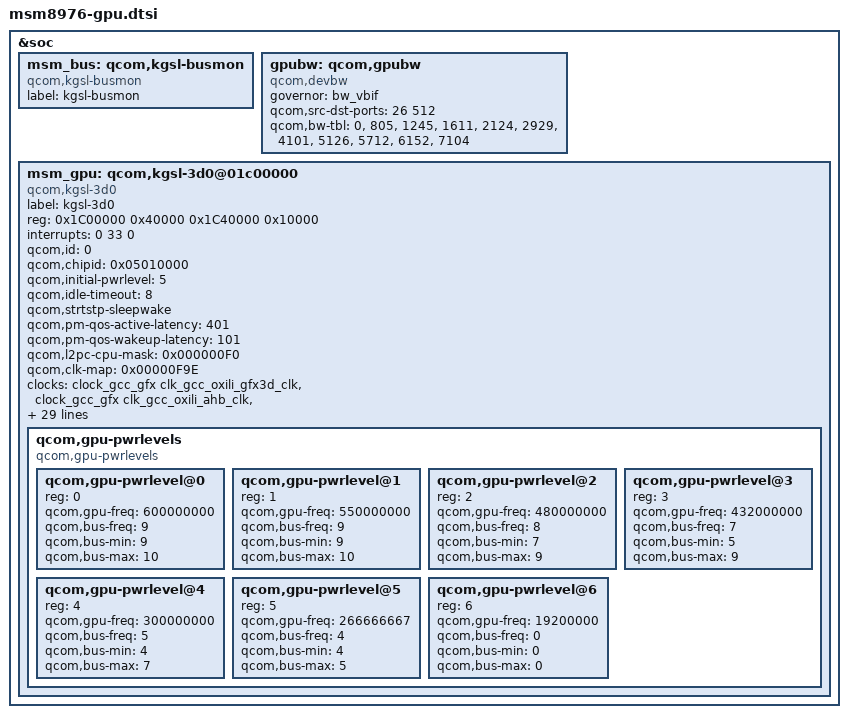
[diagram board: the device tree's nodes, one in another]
/* Copyright (c) 2015-2016, The Linux Foundation. All rights reserved.
 *
 * This program is free software; you can redistribute it and/or modify
 * it under the terms of the GNU General Public License version 2 and
 * only version 2 as published by the Free Software Foundation.
 *
 * This program is distributed in the hope that it will be useful,
 * but WITHOUT ANY WARRANTY; without even the implied warranty of
 * MERCHANTABILITY or FITNESS FOR A PARTICULAR PURPOSE.  See the
 * GNU General Public License for more details.
 */

&soc {
	msm_bus: qcom,kgsl-busmon{
		label = "kgsl-busmon";
		compatible = "qcom,kgsl-busmon";
	};

	/* Bus governor */
	gpubw: qcom,gpubw {
		compatible = "qcom,devbw";
		governor = "bw_vbif";
		qcom,src-dst-ports = <26 512>;
		qcom,bw-tbl =
			< 0 >,    /* off                            */
			< 805  >, /* DDR: 105.6 MHz BIMC:  52.8 MHz */
			< 1245 >, /* DDR: 163.2 MHz BIMC:  81.6 MHz */
			< 1611 >, /* DDR: 211.2 MHz BIMC: 105.6 MHz */
			< 2124 >, /* DDR: 278.4 MHz BIMC: 139.2 MHz */
			< 2929 >, /* DDR: 384.0 MHz BIMC: 192.0 MHz */
			< 4101 >, /* DDR: 537.6 MHz BIMC: 268.8 MHz */
			< 5126 >, /* DDR: 672.0 MHz BIMC: 336.0 MHz */
			< 5712 >, /* DDR: 748.8 MHz BIMC: 374.4 MHz */
			< 6152 >, /* DDR: 806.4 MHz BIMC: 403.2 MHz */
			< 7104 >; /* DDR: 931.2 MHz BIMC: 465.6 MHz */
	};

	msm_gpu: qcom,kgsl-3d0@01c00000 {
		label = "kgsl-3d0";
		compatible = "qcom,kgsl-3d0", "qcom,kgsl-3d";
		reg = <0x1C00000 0x40000
			   0x1C40000 0x10000>;
		reg-names = "kgsl_3d0_reg_memory" , "kgsl_3d0_shader_memory";
		interrupts = <0 33 0>;
		interrupt-names = "kgsl_3d0_irq";
		qcom,id = <0>;

		qcom,chipid = <0x05010000>;

		qcom,initial-pwrlevel = <5>;

		qcom,idle-timeout = <8>; //<HZ/12>
		qcom,strtstp-sleepwake;

		qcom,pm-qos-active-latency = <401>;
		qcom,pm-qos-wakeup-latency = <101>;

		/* Avoid L2PC on big cluster CPUs (CPU 4,5,6,7) */
		qcom,l2pc-cpu-mask = <0x000000F0>;

		/*
		 * Clocks = KGSL_CLK_CORE | KGSL_CLK_IFACE | KGSL_CLK_MEM |
		 * KGSL_CLK_MEM_IFACE | KGSL_CLK_RBBMTIMER |
		 * KGSL_CLK_GFX_GTCU  | KGSL_CLK_GFX_GTBU |
		 * KGSL_CLK_GFX_GTBU1 | KGSL_CLK_AON
		 */
		qcom,clk-map = <0x00000F9E>;

	clocks = <&clock_gcc_gfx clk_gcc_oxili_gfx3d_clk>,
		 <&clock_gcc_gfx clk_gcc_oxili_ahb_clk>,
		 <&clock_gcc_gfx clk_gcc_oxili_gmem_clk>,
		 <&clock_gcc_gfx clk_gcc_bimc_gfx_clk>,
		 <&clock_gcc_gfx clk_gcc_gtcu_ahb_clk>,
		 <&clock_gcc_gfx clk_gcc_gfx_tcu_clk>,
		 <&clock_gcc_gfx clk_gcc_gfx_tbu_clk>,
		 <&clock_gcc_gfx clk_gcc_gfx_1_tbu_clk>,
		 <&clock_gcc_gfx clk_gcc_oxili_timer_clk>,
		 <&clock_gcc_gfx clk_gcc_oxili_aon_clk>;

	clock-names =   "core_clk", "iface_clk", "mem_clk",
			"mem_iface_clk", "gtcu_iface_clk",
			"gtcu_clk", "gtbu_clk", "gtbu1_clk",
			"rbbmtimer_clk", "aon_clk";


		/* Bus Scale Settings */
		qcom,gpubw-dev = <&gpubw>;
		qcom,bus-control;
		qcom,bus-width = <16>;
		qcom,msm-bus,name = "grp3d";
		qcom,msm-bus,num-cases = <11>;
		qcom,msm-bus,num-paths = <1>;
		qcom,msm-bus,vectors-KBps =
				<26 512 0 0>,	    /*  off          */
				<26 512 0 844800>,  /* 1. 105.6  MHz */
				<26 512 0 1305600>, /* 2. 163.2  MHz */
				<26 512 0 1689600>, /* 3. 211.2  MHz */
				<26 512 0 2227200>, /* 4. 278.4  MHz */
				<26 512 0 3072000>, /* 5. 384.0  MHz */
				<26 512 0 4300800>, /* 6. 537.6  MHz */
				<26 512 0 5376000>, /* 7. 672.0  MHz */
				<26 512 0 5990400>, /* 8. 748.8  MHz */
				<26 512 0 6451200>, /* 9. 806.4  MHz */
				<26 512 0 7449600>; /*10. 931.2  MHz */

		/* GDSC oxili regulators */
		vddcx-supply = <&gdsc_oxili_cx>;
		vdd-supply = <&gdsc_oxili_gx>;

		/* IOMMU Data */
                iommu = <&gfx_iommu>;

		/* Trace bus */
		coresight-id = <67>;
		coresight-name = "coresight-gfx";
		coresight-nr-inports = <0>;
		coresight-outports = <0>;
		coresight-child-list = <&funnel_in0>;
		coresight-child-ports = <4>;

		/* Power levels */
		qcom,gpu-pwrlevels {
			#address-cells = <1>;
			#size-cells = <0>;

			compatible = "qcom,gpu-pwrlevels";

			/* TURBO */
			qcom,gpu-pwrlevel@0 {
				reg = <0>;
				qcom,gpu-freq = <600000000>;
				qcom,bus-freq = <9>;
				qcom,bus-min = <9>;
				qcom,bus-max = <10>;
			};

			/* TURBO */
			qcom,gpu-pwrlevel@1 {
				reg = <1>;
				qcom,gpu-freq = <550000000>;
				qcom,bus-freq = <9>;
				qcom,bus-min = <9>;
				qcom,bus-max = <10>;
			};

			/* NOM+ */
			qcom,gpu-pwrlevel@2 {
				reg = <2>;
				qcom,gpu-freq = <480000000>;
				qcom,bus-freq = <8>;
				qcom,bus-min = <7>;
				qcom,bus-max = <9>;
			};

			/* NOM */
			qcom,gpu-pwrlevel@3 {
				reg = <3>;
				qcom,gpu-freq = <432000000>;
				qcom,bus-freq = <7>;
				qcom,bus-min = <5>;
				qcom,bus-max = <9>;
			};

			/* SVS */
			qcom,gpu-pwrlevel@4 {
				reg = <4>;
				qcom,gpu-freq = <300000000>;
				qcom,bus-freq = <5>;
				qcom,bus-min = <4>;
				qcom,bus-max = <7>;
			};

			/* Low SVS+ */
			qcom,gpu-pwrlevel@5 {
				reg = <5>;
				qcom,gpu-freq = <266666667>;
				qcom,bus-freq = <4>;
				qcom,bus-min = <4>;
				qcom,bus-max = <5>;
			};

			qcom,gpu-pwrlevel@6 {
				reg = <6>;
				qcom,gpu-freq = <19200000>;
				qcom,bus-freq = <0>;
				qcom,bus-min = <0>;
				qcom,bus-max = <0>;
			};
		};
	};
};
